AUTOSAR XML (schema 4-0-3)
package /ComponentTypes
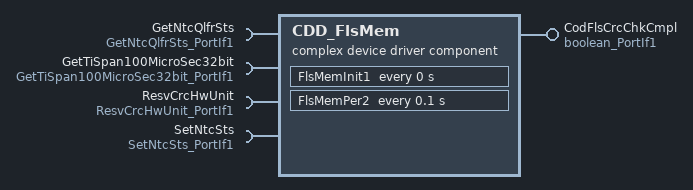
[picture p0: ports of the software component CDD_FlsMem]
  complex device driver sw component type CDD_FlsMem
    provide port CodFlsCrcChkCmpl: nonqueued-sender-com-spec{data-element=Logl, init-value=0}, provided-interface=boolean_PortIf1
    4 x require port:
      GetNtcQlfrSts: required-interface=GetNtcQlfrSts_PortIf1
      GetTiSpan100MicroSec32bit: required-interface=GetTiSpan100MicroSec32bit_PortIf1
      ResvCrcHwUnit: required-interface=ResvCrcHwUnit_PortIf1
      SetNtcSts: required-interface=SetNtcSts_PortIf1
    behavior CDD_FlsMem_InternalBehavior
      ar-typed-per-instance-memorys:
        5 x data, all with sw-calibration-access=READ-ONLY:
          CodFlsCrcChkStrtTi: type=uint32
          CodFlsSngBitErr: type=boolean
          CrcChkCmpl: type=boolean
          CrcHwIdxKey: type=uint16
          PwrOnRstCrcChkCmpl: type=boolean
      timing event FlsMemInit1_InitEvent: start-on-event=FlsMemInit1, period=0
      timing event TMT_FlsMemPer2: start-on-event=FlsMemPer2, period=0.1
      runnable FlsMemInit1
      runnable FlsMemPer2
        data-send-points:
          access SEND_CodFlsCrcChkCmpl_Logl: accessed-variable=CodFlsCrcChkCmpl.Logl
        sync call SC_GetTiSpan100MicroSec32bit_Oper: operation=GetTiSpan100MicroSec32bit.Oper, timeout=0
        sync call SC_ResvCrcHwUnit_Oper: operation=ResvCrcHwUnit.Oper, timeout=0
        sync call SC_SetNtcSts_Oper: operation=SetNtcSts.Oper, timeout=0
  swc implementation CDD_FlsMem_Implementation: behavior=CDD_FlsMem_InternalBehavior
    code-descriptors:
      code Default: artifact-descriptors=autosar-engineering-object={short-label=Default, category=SWSRC}
